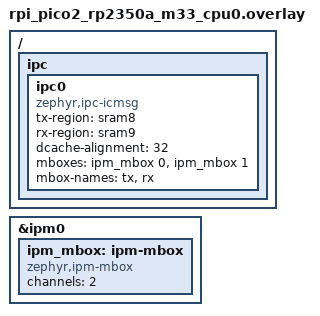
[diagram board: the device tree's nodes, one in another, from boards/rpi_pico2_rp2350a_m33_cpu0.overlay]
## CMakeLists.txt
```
#
# Copyright (c) 2022 Nordic Semiconductor ASA
#
# SPDX-License-Identifier: Apache-2.0
#

cmake_minimum_required(VERSION 3.20.0)

find_package(Zephyr REQUIRED HINTS $ENV{ZEPHYR_BASE})

if(NOT CONFIG_BOARD_NRF5340DK_NRF5340_CPUAPP AND
    NOT CONFIG_BOARD_NRF5340BSIM_NRF5340_CPUAPP AND
    NOT CONFIG_BOARD_NRF54LM20DK_NRF54LM20A_CPUAPP AND
    NOT CONFIG_BOARD_STM32H747I_DISCO AND
    NOT CONFIG_BOARD_NRF54L15DK_NRF54L15_CPUAPP AND
    NOT CONFIG_BOARD_EK_RA8P1_R7KA8P1KFLCAC_CM85 AND
    NOT CONFIG_BOARD_NRF7120DK_NRF7120_CPUAPP AND
    NOT CONFIG_BOARD_APARD32690_MAX32690_M4 AND
    NOT CONFIG_BOARD_RPI_PICO2_RP2350A_M33)
  message(FATAL_ERROR "${BOARD} is not supported for this sample")
endif()

project(ipc_service_host)

target_include_directories(app PRIVATE ${CMAKE_CURRENT_SOURCE_DIR}/common)

target_sources(app PRIVATE src/main.c)

include(ExternalProject)
```

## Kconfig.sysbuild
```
# Copyright 2023 Nordic Semiconductor ASA
#
# SPDX-License-Identifier: Apache-2.0

source "share/sysbuild/Kconfig"

config REMOTE_BOARD
string
	default "nrf5340dk/nrf5340/cpunet" if $(BOARD) = "nrf5340dk"
	default "nrf5340bsim/nrf5340/cpunet" if $(BOARD) = "nrf5340bsim"
	default "nrf54l15dk/nrf54l15/cpuflpr" if $(BOARD) = "nrf54l15dk"
	default "nrf54lm20dk/nrf54lm20a/cpuflpr" if $(BOARD) = "nrf54lm20dk"
	default "nrf7120dk/nrf7120/cpuflpr" if $(BOARD) = "nrf7120dk"
	default "stm32h747i_disco/stm32h747xx/m4" if $(BOARD) = "stm32h747i_disco"
	default "ek_ra8p1/r7ka8p1kflcac/cm33" if $(BOARD) = "ek_ra8p1"
	default "$(BOARD)/max32690/rv32" if SOC_MAX32690_M4
	default "rpi_pico2/rp2350a/m33/cpu1" if $(BOARD) = "rpi_pico2"
```

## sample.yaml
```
sample:
  name: IPC Service example integration (icmsg backend)
common:
  timeout: 30
  sysbuild: true
  tags: ipc
  harness: pytest
tests:
  sample.ipc.icmsg:
    platform_allow:
      - nrf5340dk/nrf5340/cpuapp
      - nrf5340bsim/nrf5340/cpuapp
    integration_platforms:
      - nrf5340dk/nrf5340/cpuapp
      - nrf5340bsim/nrf5340/cpuapp

  sample.ipc.icmsg.rp2350:
    platform_allow:
      - rpi_pico2/rp2350a/m33
    integration_platforms:
      - rpi_pico2/rp2350a/m33
    extra_args:
      - icmsg_SNIPPET=rp2xxx-cpu1

  sample.ipc.icbmsg.rp2350:
    platform_allow:
      - rpi_pico2/rp2350a/m33
    integration_platforms:
      - rpi_pico2/rp2350a/m33
    extra_args:
      - FILE_SUFFIX=icbmsg
      - icmsg_SNIPPET=rp2xxx-cpu1

  sample.ipc.icmsg.rp2350_xip:
    platform_allow:
      - rpi_pico2/rp2350a/m33
    integration_platforms:
      - rpi_pico2/rp2350a/m33
    extra_args:
      - SNIPPET=rp2xxx-cpu1-xip

  sample.ipc.icbmsg.rp2350_xip:
    platform_allow:
      - rpi_pico2/rp2350a/m33
    integration_platforms:
      - rpi_pico2/rp2350a/m33
    extra_args:
      - FILE_SUFFIX=icbmsg
      - SNIPPET=rp2xxx-cpu1-xip

  sample.ipc.icmsg.nrf54l:
    platform_allow:
      - nrf54l15dk/nrf54l15/cpuapp
      - nrf54lm20dk/nrf54lm20a/cpuapp
    integration_platforms:
      - nrf54l15dk/nrf54l15/cpuapp
    extra_args: icmsg_SNIPPET=nordic-flpr

  sample.ipc.icmsg.nrf54l_no_multithreading:
    platform_allow:
      - nrf54l15dk/nrf54l15/cpuapp
      - nrf54lm20dk/nrf54lm20a/cpuapp
    integration_platforms:
      - nrf54l15dk/nrf54l15/cpuapp
    extra_args:
      - icmsg_SNIPPET=nordic-flpr
      - icmsg_CONFIG_MULTITHREADING=n
      - icmsg_CONFIG_LOG_MODE_MINIMAL=y
      - remote_CONFIG_MULTITHREADING=n
      - remote_CONFIG_LOG_MODE_MINIMAL=y

  sample.ipc.icmsg.nrf54l_remote_no_multithreading:
    platform_allow:
      - nrf54l15dk/nrf54l15/cpuapp
      - nrf54lm20dk/nrf54lm20a/cpuapp
    integration_platforms:
      - nrf54l15dk/nrf54l15/cpuapp
    extra_args:
      - icmsg_SNIPPET=nordic-flpr
      - remote_CONFIG_MULTITHREADING=n
      - remote_CONFIG_LOG_MODE_MINIMAL=y

  sample.ipc.icbmsg.nrf54l:
    platform_allow:
      - nrf54l15dk/nrf54l15/cpuapp
      - nrf54lm20dk/nrf54lm20a/cpuapp
    integration_platforms:
      - nrf54l15dk/nrf54l15/cpuapp
    extra_args:
      - icmsg_SNIPPET=nordic-flpr
      - icmsg_CONFIG_IPC_SERVICE_BACKEND_ICBMSG_NUM_EP=1
      - icmsg_EXTRA_DTC_OVERLAY_FILE="boards/nrf54l_cpuapp_icbmsg.overlay"
      - remote_CONFIG_IPC_SERVICE_BACKEND_ICBMSG_NUM_EP=1
      - remote_EXTRA_DTC_OVERLAY_FILE="boards/nrf54l_cpuflpr_icbmsg.overlay"

  sample.ipc.icbmsg.nrf54l_no_multithreading:
    platform_allow:
      - nrf54l15dk/nrf54l15/cpuapp
      - nrf54lm20dk/nrf54lm20a/cpuapp
    integration_platforms:
      - nrf54l15dk/nrf54l15/cpuapp
    extra_args:
      - icmsg_SNIPPET=nordic-flpr
      - icmsg_CONFIG_IPC_SERVICE_BACKEND_ICBMSG_NUM_EP=1
      - icmsg_EXTRA_DTC_OVERLAY_FILE="boards/nrf54l_cpuapp_icbmsg.overlay"
      - icmsg_CONFIG_MULTITHREADING=n
      - icmsg_CONFIG_LOG_MODE_MINIMAL=y
      - remote_CONFIG_IPC_SERVICE_BACKEND_ICBMSG_NUM_EP=1
      - remote_EXTRA_DTC_OVERLAY_FILE="boards/nrf54l_cpuflpr_icbmsg.overlay"
      - remote_CONFIG_MULTITHREADING=n
      - remote_CONFIG_LOG_MODE_MINIMAL=y

  sample.ipc.icbmsg.nrf54l_remote_no_multithreading:
    platform_allow:
      - nrf54l15dk/nrf54l15/cpuapp
      - nrf54lm20dk/nrf54lm20a/cpuapp
    integration_platforms:
      - nrf54l15dk/nrf54l15/cpuapp
    extra_args:
      - icmsg_SNIPPET=nordic-flpr
      - icmsg_CONFIG_IPC_SERVICE_BACKEND_ICBMSG_NUM_EP=1
      - icmsg_EXTRA_DTC_OVERLAY_FILE="boards/nrf54l_cpuapp_icbmsg.overlay"
      - remote_CONFIG_IPC_SERVICE_BACKEND_ICBMSG_NUM_EP=1
      - remote_EXTRA_DTC_OVERLAY_FILE="boards/nrf54l_cpuflpr_icbmsg.overlay"
      - remote_CONFIG_MULTITHREADING=n
      - remote_CONFIG_LOG_MODE_MINIMAL=y

  sample.ipc.icmsg.nrf7120:
    platform_allow:
      - nrf7120dk/nrf7120/cpuapp
    integration_platforms:
      - nrf7120dk/nrf7120/cpuapp
    extra_args: icmsg_SNIPPET=nordic-flpr

  sample.ipc.icbmsg.nrf7120:
    platform_allow:
      - nrf7120dk/nrf7120/cpuapp
    integration_platforms:
      - nrf7120dk/nrf7120/cpuapp
    extra_args:
      - icmsg_SNIPPET=nordic-flpr
      - icmsg_CONFIG_IPC_SERVICE_BACKEND_ICBMSG_NUM_EP=1
      - icmsg_EXTRA_DTC_OVERLAY_FILE="boards/nrf7120dk_nrf7120_cpuapp_icbmsg.overlay"
      - remote_CONFIG_IPC_SERVICE_BACKEND_ICBMSG_NUM_EP=1
      - remote_EXTRA_DTC_OVERLAY_FILE="boards/nrf7120dk_nrf7120_cpuflpr_icbmsg.overlay"
```

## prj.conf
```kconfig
CONFIG_PRINTK=y

CONFIG_IPC_SERVICE=y
CONFIG_MBOX=y

CONFIG_LOG=y
CONFIG_ASSERT=y

CONFIG_SOC_LOG_LEVEL_DBG=y
```

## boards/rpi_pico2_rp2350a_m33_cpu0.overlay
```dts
/*
 * Copyright (c) 2025 Dmitrii Sharshakov <d3dx12.xx@gmail.com>
 *
 * SPDX-License-Identifier: Apache-2.0
 */

&ipm0 {
	ipm_mbox: ipm-mbox {
		compatible = "zephyr,ipm-mbox";
		#mbox-cells = <1>;
		channels = <2>;
		status = "okay";
	};
};

/ {
	ipc {
		ipc0: ipc0 {
			compatible = "zephyr,ipc-icmsg";
			tx-region = <&sram8>;
			rx-region = <&sram9>;
			dcache-alignment = <32>;
			mboxes = <&ipm_mbox 0>, <&ipm_mbox 1>;
			mbox-names = "tx", "rx";
			status = "okay";
		};
	};
};
```

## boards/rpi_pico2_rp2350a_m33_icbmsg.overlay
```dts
/*
 * Copyright (c) 2025 Dmitrii Sharshakov <d3dx12.xx@gmail.com>
 *
 * SPDX-License-Identifier: Apache-2.0
 */

&ipc0 {
	compatible = "zephyr,ipc-icbmsg";
	tx-blocks = <32>;
	rx-blocks = <32>;
};
```

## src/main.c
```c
/*
 * Copyright (c) 2022 Nordic Semiconductor ASA
 *
 * SPDX-License-Identifier: Apache-2.0
 */

#include <zephyr/kernel.h>
#include <zephyr/device.h>

#include <zephyr/ipc/ipc_service.h>
#if defined(CONFIG_SOC_NRF5340_CPUAPP)
#include <nrf53_cpunet_mgmt.h>
#endif
#include <string.h>

#include "common.h"

#include <zephyr/logging/log.h>
LOG_MODULE_REGISTER(host, LOG_LEVEL_INF);

#if defined(CONFIG_MULTITHREADING)
K_SEM_DEFINE(bound_sem, 0, 1);
#else
volatile uint32_t bound_sem = 1;
volatile uint32_t recv_sem = 1;
#endif

static unsigned char expected_message = 'A';
static size_t expected_len = PACKET_SIZE_START;
static size_t received;

static void ep_bound(void *priv)
{
	LOG_INF("IPC-service HOST ep_bound start!");
	received = 0;
#if defined(CONFIG_MULTITHREADING)
	k_sem_give(&bound_sem);
#else
	bound_sem = 0;
#endif
	expected_message = 'A';
	expected_len = PACKET_SIZE_START;
	LOG_INF("Ep bounded");
}

static void ep_unbound(void *priv)
{
	LOG_INF("Ep unbounded");
}

static void ep_recv(const void *data, size_t len, void *priv)
{
#if defined(CONFIG_ASSERT)
	struct data_packet *packet = (struct data_packet *)data;

	__ASSERT(packet->data[0] == expected_message, "Unexpected message. Expected %c, got %c",
		expected_message, packet->data[0]);
	__ASSERT(len == expected_len, "Unexpected length. Expected %zu, got %zu",
		expected_len, len);
#endif

#ifndef CONFIG_MULTITHREADING
	recv_sem = 0;
#endif

	received += len;
	expected_message++;
	expected_len++;

	if (expected_message > 'Z') {
		expected_message = 'A';
	}

	if (expected_len > sizeof(struct data_packet)) {
		expected_len = PACKET_SIZE_START;
	}
}

static void ep_error(const char *message, void *priv)
{
	LOG_ERR("ICMsg error: %s", message);
}

static int send_for_time(struct ipc_ept *ep, const int64_t sending_time_ms)
{
	struct data_packet msg = {.data[0] = 'a'};
	size_t mlen = PACKET_SIZE_START;
	size_t bytes_sent = 0;
	int ret = 0;

	LOG_INF("Perform sends for %lld [ms]", sending_time_ms);

	int64_t start = k_uptime_get();

	while ((k_uptime_get() - start) < sending_time_ms) {
		ret = ipc_service_send(ep, &msg, mlen);
		if (ret == -ENOMEM) {
			/* No space in the buffer. Retry. */
			ret = 0;
			continue;
		} else if (ret < 0) {
			LOG_ERR("Failed to send (%c) failed with ret %d", msg.data[0], ret);
			break;
		}
#if !defined(CONFIG_MULTITHREADING)
		else {
			recv_sem = 1;
		}
#endif

		msg.data[0]++;
		if (msg.data[0] > 'z') {
			msg.data[0] = 'a';
		}

		bytes_sent += mlen;
		mlen++;

		if (mlen > sizeof(struct data_packet)) {
			mlen = PACKET_SIZE_START;
		}

#if defined(CONFIG_MULTITHREADING)
		k_usleep(1);
#else
		while ((recv_sem != 0) && ((k_uptime_get() - start) < sending_time_ms)) {
		};
#endif
	}

	LOG_INF("Sent %zu [Bytes] over %lld [ms]", bytes_sent, sending_time_ms);

	return ret;
}

static struct ipc_ept_cfg ep_cfg = {
	.cb = {
		.bound    = ep_bound,
		.unbound  = ep_unbound,
		.received = ep_recv,
		.error    = ep_error,
	},
};

int main(void)
{
	const struct device *ipc0_instance;
	struct ipc_ept ep;
	int ret;

	LOG_INF("IPC-service HOST demo started");

#if defined(CONFIG_SOC_NRF5340_CPUAPP)
	LOG_INF("Run network core");
	nrf53_cpunet_enable(true);
#endif

	ipc0_instance = DEVICE_DT_GET(DT_NODELABEL(ipc0));

	ret = ipc_service_open_instance(ipc0_instance);
	if ((ret < 0) && (ret != -EALREADY)) {
		LOG_ERR("ipc_service_open_instance() failure");
		return ret;
	}
	LOG_INF("IPC-service HOST open instance complete");

	while(1) {
	ret = ipc_service_register_endpoint(ipc0_instance, &ep, &ep_cfg);
	if (ret < 0) {
		LOG_ERR("ipc_service_register_endpoint() failure");
		return ret;
	}
	LOG_INF("IPC-service HOST endpoint registered");

#if defined(CONFIG_MULTITHREADING)
	k_sem_take(&bound_sem, K_FOREVER);
#else
	while (bound_sem != 0) {
	};
#endif

	LOG_INF("IPC-service HOST took sem");
	ret = send_for_time(&ep, SENDING_TIME_MS);
	if (ret < 0) {
		LOG_ERR("send_for_time() failure");
		return ret;
	}

	LOG_INF("Wait 500ms. Let remote core finish its sends");
#if defined(CONFIG_MULTITHREADING)
	k_msleep(500);
#else
	k_busy_wait(500000);
#endif

	LOG_INF("Received %zu [Bytes] in total", received);

#if defined(CONFIG_SOC_NRF5340_CPUAPP)
	LOG_INF("Stop network core");
	nrf53_cpunet_enable(false);

	LOG_INF("Reset IPC service");

	ret = ipc_service_deregister_endpoint(&ep);
	if (ret != 0) {
		LOG_ERR("ipc_service_register_endpoint() failure");
		return ret;
	}

	/* Reset message and expected message value and len. */
	expected_message = 'A';
	expected_len = PACKET_SIZE_START;

	/* Reset bound sem. */
	ret = k_sem_init(&bound_sem, 0, 1);
	if (ret != 0) {
		LOG_ERR("k_sem_init() failure");
		return ret;
	}

	ret = ipc_service_register_endpoint(ipc0_instance, &ep, &ep_cfg);
	if (ret != 0) {
		LOG_INF("ipc_service_register_endpoint() failure");
		return ret;
	}

	LOG_INF("Run network core");
	nrf53_cpunet_enable(true);

	k_sem_take(&bound_sem, K_FOREVER);

	ret = send_for_time(&ep, SENDING_TIME_MS);
	if (ret < 0) {
		LOG_ERR("send_for_time() failure");
		return ret;
	}
#endif /* CONFIG_SOC_NRF5340_CPUAPP */

	LOG_INF("IPC-service HOST demo ended");

	ret = ipc_service_deregister_endpoint(&ep);
	if (ret != 0) {
		LOG_ERR("ipc_service_register_endpoint() failure");
		return ret;
	}

	LOG_INF("Waiting for 1s");
	k_busy_wait(1000000);
	}
	return 0;
}
```
